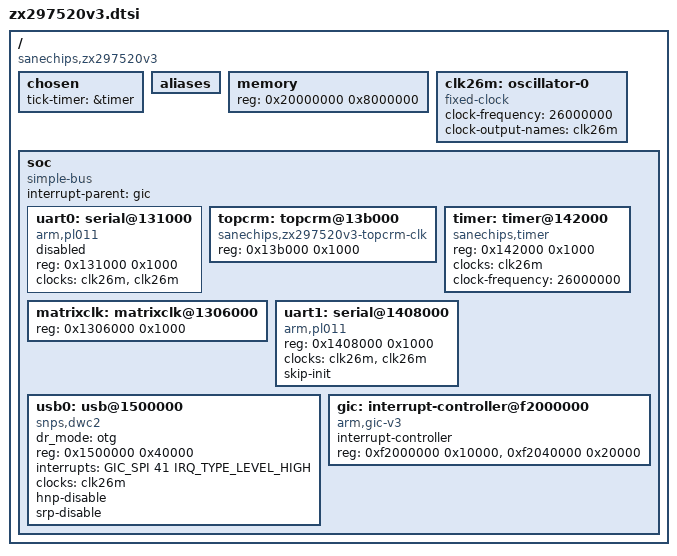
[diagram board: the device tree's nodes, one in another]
// SPDX-License-Identifier: GPL-2.0
#include <dt-bindings/interrupt-controller/irq.h>
#include <dt-bindings/interrupt-controller/arm-gic.h>

/dts-v1/;

/ {
	compatible = "sanechips,zx297520v3";
	#address-cells = <1>;
	#size-cells = <1>;

	chosen {
		tick-timer = &timer;
	};

	aliases { };
	memory {
		device_type = "memory";
		reg = <0x20000000 0x8000000>;
	};

	clk26m: oscillator-0 {
		compatible = "fixed-clock";
		#clock-cells = <0>;
		clock-frequency = <26000000>;
		clock-output-names = "clk26m";
	};


	soc {
		#address-cells = <1>;
		#size-cells = <1>;
		compatible = "simple-bus";
		interrupt-parent = <&gic>;
		ranges;

		uart0: serial@131000 {
			compatible = "arm,pl011", "arm,primecell";
			reg = <0x131000 0x1000>;
			clocks = <&clk26m>, <&clk26m>;
			clock-names = "uartclk", "apb_pclk";
			status = "disabled";
		};

		topcrm: topcrm@13b000 {
			compatible = "sanechips,zx297520v3-topcrm-clk";
			reg = <0x13b000 0x1000>;
			#clock-cells = <1>;
		};

		timer: timer@142000 {
			compatible = "sanechips,timer";
			reg = <0x142000 0x1000>;
			clocks = <&clk26m>;
			clock-names = "timer";
			clock-frequency = <26000000>;
		};

		matrixclk: matrixclk@1306000 {
			// compatible set in the board dts
			reg = <0x1306000 0x1000>;
			#clock-cells = <1>;
		};

		uart1: serial@1408000 {
			compatible = "arm,pl011", "arm,primecell";
			reg = <0x1408000 0x1000>;
			clocks = <&clk26m>, <&clk26m>;
			clock-names = "uartclk", "apb_pclk";
			skip-init;
		};

		usb0: usb@1500000 {
			compatible = "snps,dwc2";
			dr_mode = "otg";
			reg = <0x1500000 0x40000>;
			interrupts = <GIC_SPI 41 IRQ_TYPE_LEVEL_HIGH>;
			clocks = <&clk26m>;
			clock-names = "otg";
			hnp-disable;
			srp-disable;
		};

		gic: interrupt-controller@f2000000 {
			compatible = "arm,gic-v3";
			interrupt-controller;
			#interrupt-cells = <3>;
			#address-cells = <1>;
			#size-cells = <1>;
			reg = <0xf2000000 0x10000>,
			      <0xf2040000 0x20000>;
		};
	};
};
